# CY8C4248LQQ_BL583 register map
File version: 0.1
PSoC 4200 BLE
Registers are 32-bit, read-write, no defined reset value unless marked. A register's access mark holds for its fields unless they carry their own. Offsets are from the block's base; lines under a group give offsets from that group; [hi:lo] are bit positions; {n}, {i} and the like mark numbered series; 'fields as' and 'values as' point back to an identical list; <NAME> marks a mode.

## Memory map
0x00000000 uart2 — UART
0x00000000 pwmBuzzer
0x00000000 UART — Serial Communication Block
0x00000000 DisplayTimer
0x00000000 adc — Sequencing SAR ADC
0x40000000 DMAC — DMAC Registers

## uart2 — UART
Base 0x00000000
0x400F0021 RX_uart2_RX_ADDRESS1 8-bit — RX Address1 Register
0x400F0031 RX_uart2_RX_ADDRESS2 8-bit — RX Address2 Register
0x400F0041 RX_uart2_RX_DATA 8-bit — RX Data Register
0x400F0043 TX_uart2_TX_DATA 8-bit — TX Data Register
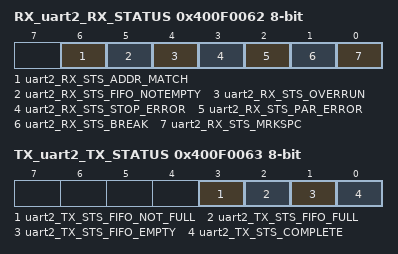
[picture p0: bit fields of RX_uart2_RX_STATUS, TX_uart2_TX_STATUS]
0x400F0062 RX_uart2_RX_STATUS 8-bit — RX status register
  [6] uart2_RX_STS_ADDR_MATCH ro, [5] uart2_RX_STS_FIFO_NOTEMPTY ro, [4] uart2_RX_STS_OVERRUN ro, [3] uart2_RX_STS_STOP_ERROR ro, [2] uart2_RX_STS_PAR_ERROR ro, [1] uart2_RX_STS_BREAK ro, [0] uart2_RX_STS_MRKSPC ro
0x400F0063 TX_uart2_TX_STATUS 8-bit — TX status register
  [3] uart2_TX_STS_FIFO_NOT_FULL ro, [2] uart2_TX_STS_FIFO_FULL ro, [1] uart2_TX_STS_FIFO_EMPTY ro, [0] uart2_TX_STS_COMPLETE ro

## pwmBuzzer
Base 0x00000000
0x400F0020 pwmBuzzer_COMPARE_Reg_ 8-bit — UDB.D0 - Assigned Compare Value
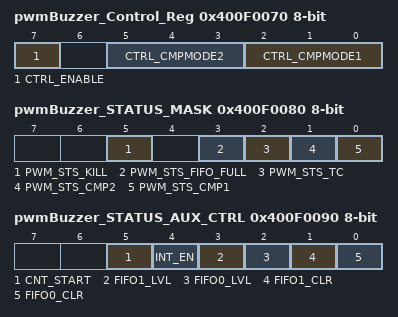
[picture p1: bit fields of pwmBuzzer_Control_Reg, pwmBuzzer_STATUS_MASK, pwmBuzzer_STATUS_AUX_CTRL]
0x400F0070 pwmBuzzer_Control_Reg 8-bit — UDB Control Register - Assigned Control Register Value
  [7] CTRL_ENABLE — Enable the PWM
  [5:3] CTRL_CMPMODE2 — Compare mode 2
  [2:0] CTRL_CMPMODE1 — Compare mode 1
0x400F0080 pwmBuzzer_STATUS_MASK 8-bit — UDB Status bits Interrupt Mask Enable Register
  [5] PWM_STS_KILL ro — Enables the Interrupt on Kill
  [3] PWM_STS_FIFO_FULL ro — FIFO Full Status Mask
  [2] PWM_STS_TC ro — Enables the Interrupt on Terminal Count
  [1] PWM_STS_CMP2 ro — Enables the Interrupt on Compare 2
  [0] PWM_STS_CMP1 ro — Enables the Interrupt on Compare 1
0x400F0090 pwmBuzzer_STATUS_AUX_CTRL 8-bit — UDB Auxilliary Control Register
  [5] CNT_START — FIFO0 clear
    0=E_CNT_START0 (Disable counter); 1=E_CNT_START1 (Enable counter)
  [4] INT_EN
    0=E_INT_EN0 (Interrupt disabled); 1=E_INT_EN1 (Interrupt enabled)
  [3] FIFO1_LVL — FIFO level
    0=E_FIFO_LVL_0 (FIFO LVL: input mode: FIFO not full; output mode: FIFO not empty); 1=E_FIFO_LVL_1 (FIFO LVL: input mode: FIFO at least 1/2 empty; output mode: FIFO at least 1/2 full)
  [2] FIFO0_LVL — FIFO level
    values as FIFO1_LVL
  [1] FIFO1_CLR — FIFO1 clear
    0=E_FIFO_CLR_0 (Normal FIFO operation); 1=E_FIFO_CLR_1 (Clear FIFO state)
  [0] FIFO0_CLR — FIFO0 clear
    values as FIFO1_CLR

## DisplayTimer
Base 0x00000000
0x40200108 COUNTER — Current counter value
0x4020010C CC — Compare / capture value
0x40200110 CC_BUF — Compare / capture buffer value
0x40200114 PERIOD — Period value
0x40200118 PERIOD_BUF — Period buffer value
